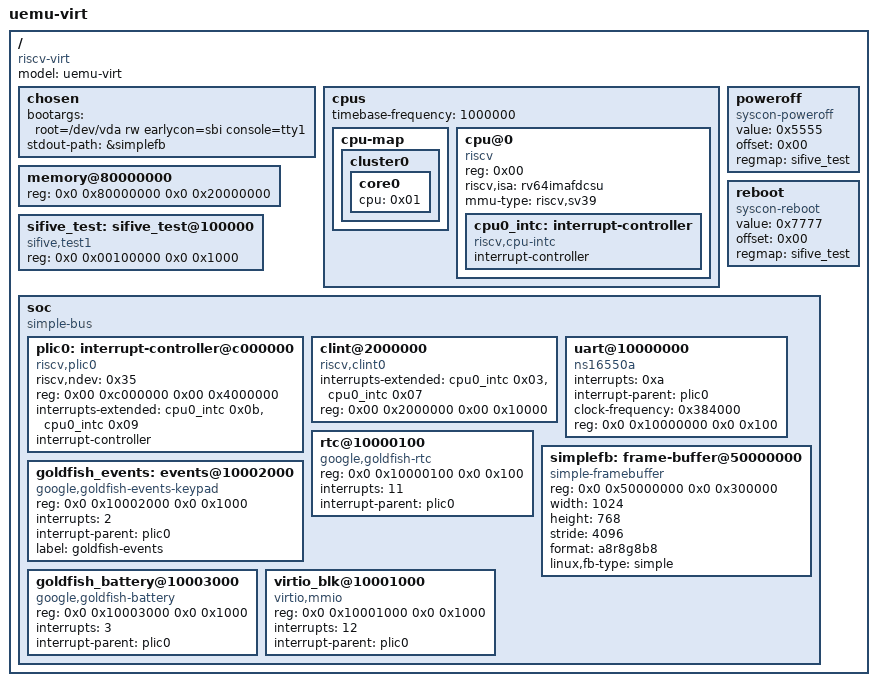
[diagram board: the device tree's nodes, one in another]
/*
 * Copyright 2025 Nuo Shen, Nanjing University
 *
 * Licensed under the Apache License, Version 2.0 (the "License");
 * you may not use this file except in compliance with the License.
 * You may obtain a copy of the License at
 *
 *     http://www.apache.org/licenses/LICENSE-2.0
 *
 * Unless required by applicable law or agreed to in writing, software
 * distributed under the License is distributed on an "AS IS" BASIS,
 * WITHOUT WARRANTIES OR CONDITIONS OF ANY KIND, either express or implied.
 * See the License for the specific language governing permissions and
 * limitations under the License.
 */

/dts-v1/;

/ {
    #address-cells = <0x02>;
    #size-cells = <0x02>;
    compatible = "riscv-virt";
    model = "uemu-virt";

    chosen {
        bootargs = "root=/dev/vda rw earlycon=sbi console=tty1";
        stdout-path = &simplefb;
    };

    cpus {
        #address-cells = <0x01>;
        #size-cells = <0x00>;
        timebase-frequency = <1000000>;

        cpu-map {
            cluster0 {
                core0 {
                    cpu = <0x01>;
                };
            };
        };

        cpu@0 {
            phandle = <0x01>;
            device_type = "cpu";
            reg = <0x00>;
            status = "okay";
            compatible = "riscv";
            riscv,isa = "rv64imafdcsu";
            mmu-type = "riscv,sv39";

            cpu0_intc: interrupt-controller {
                #interrupt-cells = <0x01>;
                interrupt-controller;
                compatible = "riscv,cpu-intc";
                phandle = <0x02>;
            };
        };
    };

    memory@80000000 {
        device_type = "memory";
        reg = <0x0 0x80000000 0x0 0x20000000>;
    };

    sifive_test: sifive_test@100000 {
        phandle = <0x04>;
        reg = <0x0 0x00100000 0x0 0x1000>;
        compatible = "sifive,test1\0sifive,test0\0syscon";
    };

    poweroff {
        value = <0x5555>;
        offset = <0x00>;
        regmap = <&sifive_test>;
        compatible = "syscon-poweroff";
    };

    reboot {
        value = <0x7777>;
        offset = <0x00>;
        regmap = <&sifive_test>;
        compatible = "syscon-reboot";
    };

    soc {
        #address-cells = <0x02>;
        #size-cells = <0x02>;
        compatible = "simple-bus";
        ranges;

        plic0: interrupt-controller@c000000 {
            phandle = <0x03>;
            riscv,ndev = <0x35>;
            reg = <0x00 0xc000000 0x00 0x4000000>;
            interrupts-extended = <&cpu0_intc 0x0b &cpu0_intc 0x09>;
            interrupt-controller;
            compatible = "riscv,plic0";
            #interrupt-cells = <0x01>;
            #address-cells = <0x00>;
        };

        clint@2000000 {
            interrupts-extended = <&cpu0_intc 0x03 &cpu0_intc 0x07>;
            reg = <0x00 0x2000000 0x00 0x10000>;
            compatible = "riscv,clint0";
        };

        uart@10000000 {
            interrupts = <0xa>;
            interrupt-parent = <&plic0>;
            clock-frequency = <0x384000>;
            reg = <0x0 0x10000000 0x0 0x100>;
            compatible = "ns16550a";
        };

        rtc@10000100 {
            compatible = "google,goldfish-rtc";
            reg = <0x0 0x10000100 0x0 0x100>;
            interrupts = <11>;
            interrupt-parent = <&plic0>;
        };

        simplefb: frame-buffer@50000000 {
            compatible = "simple-framebuffer";
            reg = <0x0 0x50000000 0x0 0x300000>;
            width = <1024>;
            height = <768>;
            stride = <4096>;
            format = "a8r8g8b8";
            status = "okay";
            linux,fb-type = "simple";
        };

        goldfish_events: events@10002000 {
            compatible = "google,goldfish-events-keypad";
            reg = <0x0 0x10002000 0x0 0x1000>;
            interrupts = <2>;
            interrupt-parent = <&plic0>;
            label = "goldfish-events";
            status = "okay";
        };

        goldfish_battery@10003000 {
            compatible = "google,goldfish-battery";
            reg = <0x0 0x10003000 0x0 0x1000>;
            interrupts = <3>;
            interrupt-parent = <&plic0>;
            status = "okay";
        };

        virtio_blk@10001000 {
            compatible = "virtio,mmio";
            reg = <0x0 0x10001000 0x0 0x1000>;
            interrupts = <12>;
            interrupt-parent = <&plic0>;
        };
    };
};
